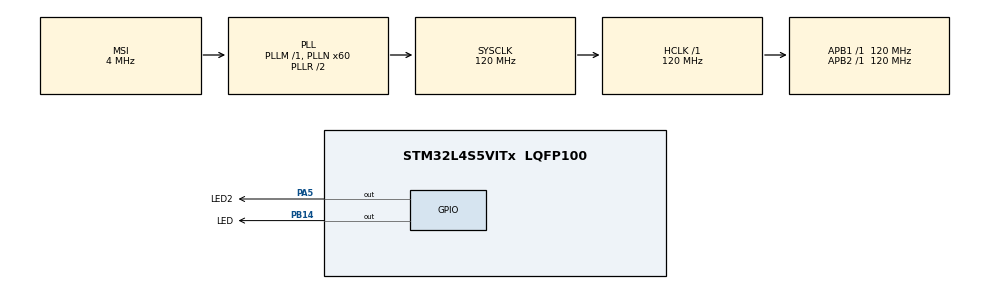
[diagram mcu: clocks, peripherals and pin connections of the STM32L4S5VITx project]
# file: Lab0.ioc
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Mcu.Family=STM32L4
Mcu.Name=STM32L4S5VITx
Mcu.Package=LQFP100
NVIC.PriorityGroup=NVIC_PRIORITYGROUP_4
NVIC.TIM2_IRQn=true\:0\:0\:false\:false\:true\:true\:true\:true
PA5.GPIO_Label=LED2
PA5.Signal=GPIO_Output
PB14.GPIO_Label=LED
PB14.Signal=GPIO_Output
ProjectManager.HeapSize=0x200
ProjectManager.StackSize=0x400
ProjectManager.TargetToolchain=STM32CubeIDE
RCC.ADCFreq_Value=48000000
RCC.AHBFreq_Value=120000000
RCC.APB1Freq_Value=120000000
RCC.APB1TimFreq_Value=120000000
RCC.APB2Freq_Value=120000000
RCC.APB2TimFreq_Value=120000000
RCC.CortexFreq_Value=120000000
RCC.HCLKFreq_Value=120000000
RCC.HSE_VALUE=8000000
RCC.HSI48_VALUE=48000000
RCC.HSI_VALUE=16000000
RCC.LSE_VALUE=32768
RCC.MSI_VALUE=4000000
RCC.PLLN=60
RCC.PLLSAI1N=24
RCC.SYSCLKFreq_VALUE=120000000
RCC.SYSCLKSource=RCC_SYSCLKSOURCE_PLLCLK
RCC.USBFreq_Value=48000000
RCC.VCOOutputFreq_Value=240000000
TIM2.Period=3000
TIM2.Prescaler=40000
VP_TIM2_VS_ClockSourceINT.Mode=Internal
board=B-L4S5I-IOT01A

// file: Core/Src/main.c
/* USER CODE BEGIN Header */
/**
  ******************************************************************************
  * @file           : main.c
  * @brief          : Main program body
  ******************************************************************************
  * @attention
  *
  * Copyright (c) 2023 STMicroelectronics.
  * All rights reserved.
  *
  * This software is licensed under terms that can be found in the LICENSE file
  * in the root directory of this software component.
  * If no LICENSE file comes with this software, it is provided AS-IS.
  *
  ******************************************************************************
  */
/* USER CODE END Header */
#include "main.h"

TIM_HandleTypeDef htim2;

void SystemClock_Config(void);
static void MX_GPIO_Init(void);
static void MX_TIM2_Init(void);

int main(void)
{

  /* MCU Configuration--------------------------------------------------------*/

  /* Reset of all peripherals, Initializes the Flash interface and the Systick. */
  HAL_Init();

  /* Configure the system clock */
  SystemClock_Config();

  /* Initialize all configured peripherals */
  MX_GPIO_Init();
  MX_TIM2_Init();
  /* USER CODE BEGIN 2 */
  // start the timer and associated interrupt
  HAL_TIM_Base_Start_IT(&htim2);
  /* USER CODE END 2 */

  /* Infinite loop */
  while (1)
  {

  }
}

void SystemClock_Config(void)
{
  RCC_OscInitTypeDef RCC_OscInitStruct = {0};
  RCC_ClkInitTypeDef RCC_ClkInitStruct = {0};

  /** Configure the main internal regulator output voltage
  */
  if (HAL_PWREx_ControlVoltageScaling(PWR_REGULATOR_VOLTAGE_SCALE1_BOOST) != HAL_OK)
  {
    Error_Handler();
  }

  /** Initializes the RCC Oscillators according to the specified parameters
  * in the RCC_OscInitTypeDef structure.
  */
  RCC_OscInitStruct.OscillatorType = RCC_OSCILLATORTYPE_MSI;
  RCC_OscInitStruct.MSIState = RCC_MSI_ON;
  RCC_OscInitStruct.MSICalibrationValue = 0;
  RCC_OscInitStruct.MSIClockRange = RCC_MSIRANGE_6;
  RCC_OscInitStruct.PLL.PLLState = RCC_PLL_ON;
  RCC_OscInitStruct.PLL.PLLSource = RCC_PLLSOURCE_MSI;
  RCC_OscInitStruct.PLL.PLLM = 1;
  RCC_OscInitStruct.PLL.PLLN = 60;
  RCC_OscInitStruct.PLL.PLLP = RCC_PLLP_DIV2;
  RCC_OscInitStruct.PLL.PLLQ = RCC_PLLQ_DIV2;
  RCC_OscInitStruct.PLL.PLLR = RCC_PLLR_DIV2;
  if (HAL_RCC_OscConfig(&RCC_OscInitStruct) != HAL_OK)
  {
    Error_Handler();
  }

  /** Initializes the CPU, AHB and APB buses clocks
  */
  RCC_ClkInitStruct.ClockType = RCC_CLOCKTYPE_HCLK|RCC_CLOCKTYPE_SYSCLK
                              |RCC_CLOCKTYPE_PCLK1|RCC_CLOCKTYPE_PCLK2;
  RCC_ClkInitStruct.SYSCLKSource = RCC_SYSCLKSOURCE_PLLCLK;
  RCC_ClkInitStruct.AHBCLKDivider = RCC_SYSCLK_DIV1;
  RCC_ClkInitStruct.APB1CLKDivider = RCC_HCLK_DIV1;
  RCC_ClkInitStruct.APB2CLKDivider = RCC_HCLK_DIV1;

  if (HAL_RCC_ClockConfig(&RCC_ClkInitStruct, FLASH_LATENCY_5) != HAL_OK)
  {
    Error_Handler();
  }
}

static void MX_TIM2_Init(void)
{

  TIM_ClockConfigTypeDef sClockSourceConfig = {0};
  TIM_MasterConfigTypeDef sMasterConfig = {0};

  htim2.Instance = TIM2;
  htim2.Init.Prescaler = 40000;
  htim2.Init.CounterMode = TIM_COUNTERMODE_UP;
  htim2.Init.Period = 3000;
  htim2.Init.ClockDivision = TIM_CLOCKDIVISION_DIV1;
  htim2.Init.AutoReloadPreload = TIM_AUTORELOAD_PRELOAD_DISABLE;
  if (HAL_TIM_Base_Init(&htim2) != HAL_OK)
  {
    Error_Handler();
  }
  sClockSourceConfig.ClockSource = TIM_CLOCKSOURCE_INTERNAL;
  if (HAL_TIM_ConfigClockSource(&htim2, &sClockSourceConfig) != HAL_OK)
  {
    Error_Handler();
  }
  sMasterConfig.MasterOutputTrigger = TIM_TRGO_RESET;
  sMasterConfig.MasterSlaveMode = TIM_MASTERSLAVEMODE_DISABLE;
  if (HAL_TIMEx_MasterConfigSynchronization(&htim2, &sMasterConfig) != HAL_OK)
  {
    Error_Handler();
  }

}

static void MX_GPIO_Init(void)
{
  GPIO_InitTypeDef GPIO_InitStruct = {0};

  /* GPIO Ports Clock Enable */
  __HAL_RCC_GPIOA_CLK_ENABLE();
  __HAL_RCC_GPIOB_CLK_ENABLE();

  /*Configure GPIO pin Output Level */
  HAL_GPIO_WritePin(LED2_GPIO_Port, LED2_Pin, GPIO_PIN_RESET);

  /*Configure GPIO pin Output Level */
  HAL_GPIO_WritePin(LED_GPIO_Port, LED_Pin, GPIO_PIN_RESET);

  /*Configure GPIO pin : LED2_Pin */
  GPIO_InitStruct.Pin = LED2_Pin;
  GPIO_InitStruct.Mode = GPIO_MODE_OUTPUT_PP;
  GPIO_InitStruct.Pull = GPIO_NOPULL;
  GPIO_InitStruct.Speed = GPIO_SPEED_FREQ_LOW;
  HAL_GPIO_Init(LED2_GPIO_Port, &GPIO_InitStruct);

  /*Configure GPIO pin : LED_Pin */
  GPIO_InitStruct.Pin = LED_Pin;
  GPIO_InitStruct.Mode = GPIO_MODE_OUTPUT_PP;
  GPIO_InitStruct.Pull = GPIO_NOPULL;
  GPIO_InitStruct.Speed = GPIO_SPEED_FREQ_LOW;
  HAL_GPIO_Init(LED_GPIO_Port, &GPIO_InitStruct);

}

/* USER CODE BEGIN 4 */

/**
 * @brief Interrupt handler for TIM2; toggle LED.
 * @retval None
 */
 void HAL_TIM_PeriodElapsedCallback(TIM_HandleTypeDef *htim){
	 HAL_GPIO_TogglePin(LED_GPIO_Port, LED_Pin);
	 HAL_GPIO_TogglePin(LED2_GPIO_Port, LED2_Pin);
 }
/* USER CODE END 4 */

void Error_Handler(void)
{
  __disable_irq();
  while (1)
  {
  }
}
